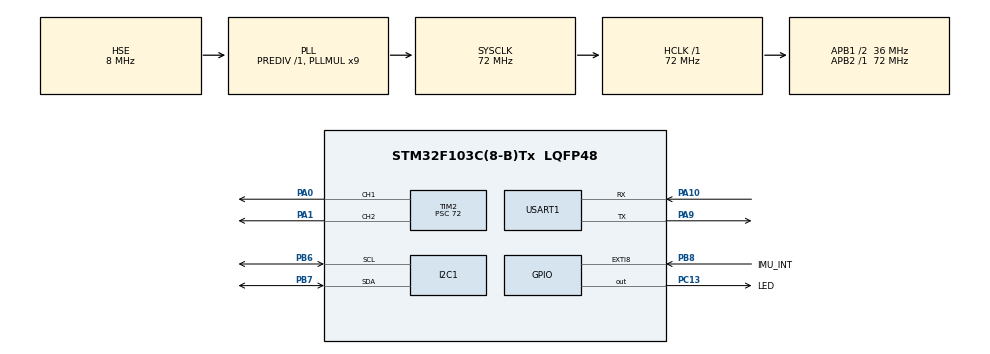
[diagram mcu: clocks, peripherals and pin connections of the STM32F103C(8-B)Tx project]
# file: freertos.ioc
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FREERTOS.MEMORY_ALLOCATION=1
FREERTOS.Tasks01=defaultTask,0,128,StartDefaultTask,Default,NULL,Static,defaultTaskBuffer,defaultTaskControlBlock
Mcu.Family=STM32F1
Mcu.Name=STM32F103C(8-B)Tx
Mcu.Package=LQFP48
NVIC.EXTI9_5_IRQn=true\:5\:0\:false\:false\:true\:true\:true
NVIC.I2C1_ER_IRQn=true\:5\:0\:false\:false\:true\:true\:true
NVIC.I2C1_EV_IRQn=true\:5\:0\:false\:false\:true\:true\:true
NVIC.PriorityGroup=NVIC_PRIORITYGROUP_4
NVIC.TIM1_UP_IRQn=true\:0\:0\:false\:false\:true\:false\:false
NVIC.TimeBase=TIM1_UP_IRQn
NVIC.TimeBaseIP=TIM1
NVIC.USART1_IRQn=true\:5\:0\:false\:false\:true\:true\:true
PA0-WKUP.GPIO_ModeDefaultPP=GPIO_MODE_AF_PP
PA0-WKUP.GPIO_Speed=GPIO_SPEED_FREQ_LOW
PA0-WKUP.Signal=S_TIM2_CH1_ETR
PA1.Signal=S_TIM2_CH2
PA10.Mode=Asynchronous
PA10.Signal=USART1_RX
PA13.Mode=Trace_Asynchronous_SW
PA13.Signal=SYS_JTMS-SWDIO
PA14.Mode=Trace_Asynchronous_SW
PA14.Signal=SYS_JTCK-SWCLK
PA9.Mode=Asynchronous
PA9.Signal=USART1_TX
PB3.Mode=Trace_Asynchronous_SW
PB3.Signal=SYS_JTDO-TRACESWO
PB6.Mode=I2C
PB6.Signal=I2C1_SCL
PB7.Mode=I2C
PB7.Signal=I2C1_SDA
PB8.GPIO_Label=IMU_INT
PB8.GPIO_ModeDefaultEXTI=GPIO_MODE_IT_RISING
PB8.GPIO_PuPd=GPIO_NOPULL
PB8.Signal=GPXTI8
PC13-TAMPER-RTC.GPIO_Label=LED
PC13-TAMPER-RTC.GPIO_ModeDefaultOutputPP=GPIO_MODE_OUTPUT_PP
PC13-TAMPER-RTC.GPIO_PuPd=GPIO_NOPULL
PC13-TAMPER-RTC.GPIO_Speed=GPIO_SPEED_FREQ_LOW
PC13-TAMPER-RTC.PinState=GPIO_PIN_RESET
PC13-TAMPER-RTC.Signal=GPIO_Output
PD0-OSC_IN.Mode=HSE-External-Oscillator
PD0-OSC_IN.Signal=RCC_OSC_IN
PD1-OSC_OUT.Mode=HSE-External-Oscillator
PD1-OSC_OUT.Signal=RCC_OSC_OUT
ProjectManager.HeapSize=0x200
ProjectManager.StackSize=0x400
ProjectManager.TargetToolchain=Makefile
RCC.AHBFreq_Value=72000000
RCC.APB1CLKDivider=RCC_HCLK_DIV2
RCC.APB1Freq_Value=36000000
RCC.APB1TimFreq_Value=72000000
RCC.APB2Freq_Value=72000000
RCC.APB2TimFreq_Value=72000000
RCC.HCLKFreq_Value=72000000
RCC.PLLMUL=RCC_PLL_MUL9
RCC.PLLSourceVirtual=RCC_PLLSOURCE_HSE
RCC.SYSCLKFreq_VALUE=72000000
RCC.SYSCLKSource=RCC_SYSCLKSOURCE_PLLCLK
RCC.USBFreq_Value=72000000
SH.S_TIM2_CH1_ETR.0=TIM2_CH1,PWM Generation1 CH1
SH.S_TIM2_CH2.0=TIM2_CH2,PWM Generation2 CH2
TIM2.Channel-PWM\ Generation1\ CH1=TIM_CHANNEL_1
TIM2.Channel-PWM\ Generation2\ CH2=TIM_CHANNEL_2
TIM2.Period=20000
TIM2.Prescaler=72
USART1.VirtualMode=VM_ASYNC
VP_FREERTOS_VS_ENABLE.Mode=Enabled
VP_SYS_VS_tim1.Mode=TIM1
board=custom

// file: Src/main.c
/**
  ******************************************************************************
  * @file           : main.c
  * @brief          : Main program body
  ******************************************************************************
  * This notice applies to any and all portions of this file
  * that are not between comment pairs USER CODE BEGIN and
  * USER CODE END. Other portions of this file, whether
  * inserted by the user or by software development tools
  * are owned by their respective copyright owners.
  *
  * Copyright (c) 2018 STMicroelectronics International N.V.
  * All rights reserved.
  *
  * Redistribution and use in source and binary forms, with or without
  * modification, are permitted, provided that the following conditions are met:
  *
  * 1. Redistribution of source code must retain the above copyright notice,
  *    this list of conditions and the following disclaimer.
  * 2. Redistributions in binary form must reproduce the above copyright notice,
  *    this list of conditions and the following disclaimer in the documentation
  *    and/or other materials provided with the distribution.
  * 3. Neither the name of STMicroelectronics nor the names of other
  *    contributors to this software may be used to endorse or promote products
  *    derived from this software without specific written permission.
  * 4. This software, including modifications and/or derivative works of this
  *    software, must execute solely and exclusively on microcontroller or
  *    microprocessor devices manufactured by or for STMicroelectronics.
  * 5. Redistribution and use of this software other than as permitted under
  *    this license is void and will automatically terminate your rights under
  *    this license.
  *
  * THIS SOFTWARE IS PROVIDED BY STMICROELECTRONICS AND CONTRIBUTORS "AS IS"
  * AND ANY EXPRESS, IMPLIED OR STATUTORY WARRANTIES, INCLUDING, BUT NOT
  * LIMITED TO, THE IMPLIED WARRANTIES OF MERCHANTABILITY, FITNESS FOR A
  * PARTICULAR PURPOSE AND NON-INFRINGEMENT OF THIRD PARTY INTELLECTUAL PROPERTY
  * RIGHTS ARE DISCLAIMED TO THE FULLEST EXTENT PERMITTED BY LAW. IN NO EVENT
  * SHALL STMICROELECTRONICS OR CONTRIBUTORS BE LIABLE FOR ANY DIRECT, INDIRECT,
  * INCIDENTAL, SPECIAL, EXEMPLARY, OR CONSEQUENTIAL DAMAGES (INCLUDING, BUT NOT
  * LIMITED TO, PROCUREMENT OF SUBSTITUTE GOODS OR SERVICES; LOSS OF USE, DATA,
  * OR PROFITS; OR BUSINESS INTERRUPTION) HOWEVER CAUSED AND ON ANY THEORY OF
  * LIABILITY, WHETHER IN CONTRACT, STRICT LIABILITY, OR TORT (INCLUDING
  * NEGLIGENCE OR OTHERWISE) ARISING IN ANY WAY OUT OF THE USE OF THIS SOFTWARE,
  * EVEN IF ADVISED OF THE POSSIBILITY OF SUCH DAMAGE.
  *
  ******************************************************************************
  */
#include "main.h"
#include "stm32f1xx_hal.h"
#include "cmsis_os.h"

/* USER CODE BEGIN Includes */
#include "FreeRTOS.h"
#include "string.h"
#include "terminal.h"
#include "imu.h"
#include "pwm.h"

/* USER CODE END Includes */

I2C_HandleTypeDef hi2c1;

TIM_HandleTypeDef htim2;

UART_HandleTypeDef huart1;

osThreadId defaultTaskHandle;
uint32_t defaultTaskBuffer[ 128 ];
osStaticThreadDef_t defaultTaskControlBlock;

/* USER CODE BEGIN PV */
/* Private variables ---------------------------------------------------------*/

/* USER CODE END PV */

void SystemClock_Config(void);
static void MX_GPIO_Init(void);
static void MX_USART1_UART_Init(void);
static void MX_I2C1_Init(void);
static void MX_TIM2_Init(void);
void StartDefaultTask(void const * argument);

void HAL_TIM_MspPostInit(TIM_HandleTypeDef *htim);

/* USER CODE BEGIN PFP */
/* Private function prototypes -----------------------------------------------*/

/* USER CODE END PFP */

int main(void)
{

  /* MCU Configuration----------------------------------------------------------*/

  /* Reset of all peripherals, Initializes the Flash interface and the Systick. */
  HAL_Init();

  /* Configure the system clock */
  SystemClock_Config();

  /* Initialize all configured peripherals */
  MX_GPIO_Init();
  MX_USART1_UART_Init();
  MX_I2C1_Init();
  MX_TIM2_Init();
  /* USER CODE BEGIN 2 */

  terminal_init(&huart1);
  imu_init(&hi2c1);
  pwm_init(&htim2);

  /* USER CODE END 2 */

  /* Create the thread(s) */
  /* definition and creation of defaultTask */
  osThreadStaticDef(defaultTask, StartDefaultTask, osPriorityNormal, 0, 128, defaultTaskBuffer, &defaultTaskControlBlock);
  defaultTaskHandle = osThreadCreate(osThread(defaultTask), NULL);

  /* Start scheduler */
  osKernelStart();

  /* We should never get here as control is now taken by the scheduler */

  /* Infinite loop */
  while (1)
  {

  }

}

void SystemClock_Config(void)
{

  RCC_OscInitTypeDef RCC_OscInitStruct;
  RCC_ClkInitTypeDef RCC_ClkInitStruct;

    /**Initializes the CPU, AHB and APB busses clocks
    */
  RCC_OscInitStruct.OscillatorType = RCC_OSCILLATORTYPE_HSE;
  RCC_OscInitStruct.HSEState = RCC_HSE_ON;
  RCC_OscInitStruct.HSEPredivValue = RCC_HSE_PREDIV_DIV1;
  RCC_OscInitStruct.HSIState = RCC_HSI_ON;
  RCC_OscInitStruct.PLL.PLLState = RCC_PLL_ON;
  RCC_OscInitStruct.PLL.PLLSource = RCC_PLLSOURCE_HSE;
  RCC_OscInitStruct.PLL.PLLMUL = RCC_PLL_MUL9;
  if (HAL_RCC_OscConfig(&RCC_OscInitStruct) != HAL_OK)
  {
    _Error_Handler(__FILE__, __LINE__);
  }

    /**Initializes the CPU, AHB and APB busses clocks
    */
  RCC_ClkInitStruct.ClockType = RCC_CLOCKTYPE_HCLK|RCC_CLOCKTYPE_SYSCLK
                              |RCC_CLOCKTYPE_PCLK1|RCC_CLOCKTYPE_PCLK2;
  RCC_ClkInitStruct.SYSCLKSource = RCC_SYSCLKSOURCE_PLLCLK;
  RCC_ClkInitStruct.AHBCLKDivider = RCC_SYSCLK_DIV1;
  RCC_ClkInitStruct.APB1CLKDivider = RCC_HCLK_DIV2;
  RCC_ClkInitStruct.APB2CLKDivider = RCC_HCLK_DIV1;

  if (HAL_RCC_ClockConfig(&RCC_ClkInitStruct, FLASH_LATENCY_2) != HAL_OK)
  {
    _Error_Handler(__FILE__, __LINE__);
  }

    /**Configure the Systick interrupt time
    */
  HAL_SYSTICK_Config(HAL_RCC_GetHCLKFreq()/1000);

    /**Configure the Systick
    */
  HAL_SYSTICK_CLKSourceConfig(SYSTICK_CLKSOURCE_HCLK);

  /* SysTick_IRQn interrupt configuration */
  HAL_NVIC_SetPriority(SysTick_IRQn, 15, 0);
}

/* I2C1 init function */
static void MX_I2C1_Init(void)
{

  hi2c1.Instance = I2C1;
  hi2c1.Init.ClockSpeed = 100000;
  hi2c1.Init.DutyCycle = I2C_DUTYCYCLE_2;
  hi2c1.Init.OwnAddress1 = 0;
  hi2c1.Init.AddressingMode = I2C_ADDRESSINGMODE_7BIT;
  hi2c1.Init.DualAddressMode = I2C_DUALADDRESS_DISABLE;
  hi2c1.Init.OwnAddress2 = 0;
  hi2c1.Init.GeneralCallMode = I2C_GENERALCALL_DISABLE;
  hi2c1.Init.NoStretchMode = I2C_NOSTRETCH_DISABLE;
  if (HAL_I2C_Init(&hi2c1) != HAL_OK)
  {
    _Error_Handler(__FILE__, __LINE__);
  }

}

/* TIM2 init function */
static void MX_TIM2_Init(void)
{

  TIM_MasterConfigTypeDef sMasterConfig;
  TIM_OC_InitTypeDef sConfigOC;

  htim2.Instance = TIM2;
  htim2.Init.Prescaler = 72;
  htim2.Init.CounterMode = TIM_COUNTERMODE_UP;
  htim2.Init.Period = 20000;
  htim2.Init.ClockDivision = TIM_CLOCKDIVISION_DIV1;
  htim2.Init.AutoReloadPreload = TIM_AUTORELOAD_PRELOAD_DISABLE;
  if (HAL_TIM_PWM_Init(&htim2) != HAL_OK)
  {
    _Error_Handler(__FILE__, __LINE__);
  }

  sMasterConfig.MasterOutputTrigger = TIM_TRGO_RESET;
  sMasterConfig.MasterSlaveMode = TIM_MASTERSLAVEMODE_DISABLE;
  if (HAL_TIMEx_MasterConfigSynchronization(&htim2, &sMasterConfig) != HAL_OK)
  {
    _Error_Handler(__FILE__, __LINE__);
  }

  sConfigOC.OCMode = TIM_OCMODE_PWM1;
  sConfigOC.Pulse = 0;
  sConfigOC.OCPolarity = TIM_OCPOLARITY_HIGH;
  sConfigOC.OCFastMode = TIM_OCFAST_DISABLE;
  if (HAL_TIM_PWM_ConfigChannel(&htim2, &sConfigOC, TIM_CHANNEL_1) != HAL_OK)
  {
    _Error_Handler(__FILE__, __LINE__);
  }

  if (HAL_TIM_PWM_ConfigChannel(&htim2, &sConfigOC, TIM_CHANNEL_2) != HAL_OK)
  {
    _Error_Handler(__FILE__, __LINE__);
  }

  HAL_TIM_MspPostInit(&htim2);

}

/* USART1 init function */
static void MX_USART1_UART_Init(void)
{

  huart1.Instance = USART1;
  huart1.Init.BaudRate = 115200;
  huart1.Init.WordLength = UART_WORDLENGTH_8B;
  huart1.Init.StopBits = UART_STOPBITS_1;
  huart1.Init.Parity = UART_PARITY_NONE;
  huart1.Init.Mode = UART_MODE_TX_RX;
  huart1.Init.HwFlowCtl = UART_HWCONTROL_NONE;
  huart1.Init.OverSampling = UART_OVERSAMPLING_16;
  if (HAL_UART_Init(&huart1) != HAL_OK)
  {
    _Error_Handler(__FILE__, __LINE__);
  }

}

/** Configure pins as
        * Analog
        * Input
        * Output
        * EVENT_OUT
        * EXTI
*/
static void MX_GPIO_Init(void)
{

  GPIO_InitTypeDef GPIO_InitStruct;

  /* GPIO Ports Clock Enable */
  __HAL_RCC_GPIOC_CLK_ENABLE();
  __HAL_RCC_GPIOD_CLK_ENABLE();
  __HAL_RCC_GPIOA_CLK_ENABLE();
  __HAL_RCC_GPIOB_CLK_ENABLE();

  /*Configure GPIO pin Output Level */
  HAL_GPIO_WritePin(LED_GPIO_Port, LED_Pin, GPIO_PIN_RESET);

  /*Configure GPIO pin : LED_Pin */
  GPIO_InitStruct.Pin = LED_Pin;
  GPIO_InitStruct.Mode = GPIO_MODE_OUTPUT_PP;
  GPIO_InitStruct.Pull = GPIO_NOPULL;
  GPIO_InitStruct.Speed = GPIO_SPEED_FREQ_LOW;
  HAL_GPIO_Init(LED_GPIO_Port, &GPIO_InitStruct);

  /*Configure GPIO pin : IMU_INT_Pin */
  GPIO_InitStruct.Pin = IMU_INT_Pin;
  GPIO_InitStruct.Mode = GPIO_MODE_IT_RISING;
  GPIO_InitStruct.Pull = GPIO_NOPULL;
  HAL_GPIO_Init(IMU_INT_GPIO_Port, &GPIO_InitStruct);

  /* EXTI interrupt init*/
  HAL_NVIC_SetPriority(EXTI9_5_IRQn, 5, 0);
  HAL_NVIC_EnableIRQ(EXTI9_5_IRQn);

}

/* USER CODE BEGIN 4 */
void HAL_UART_RxCpltCallback(UART_HandleTypeDef *huart) {
  if (huart == terminal_huart) {
    TerminalRxCallback();
  }
}

/* USER CODE END 4 */

void StartDefaultTask(void const * argument)
{

  /* USER CODE BEGIN 5 */
  //char *string = "Hello world!\n";
  //char read[100];
  /* Infinite loop */
  for(;;)
  {
    // Blink the LED
    LED_GPIO_Port->ODR ^= LED_Pin;
    osDelay(1000);
    /*
    HAL_UART_Transmit(&huart1, (uint8_t *)string, strlen(string), 1000);
    HAL_UART_Receive(&huart1, (uint8_t *)read, 100, 1000);
    if (memcmp(read, "on", strlen("on")) == 0) {
      led_config = 1;
    } else if (memcmp(read, "off", strlen("off")) == 0) {
      led_config = 0;
    }
    */
  }
  /* USER CODE END 5 */
}

void HAL_TIM_PeriodElapsedCallback(TIM_HandleTypeDef *htim)
{
  if (htim->Instance == TIM1) {
    HAL_IncTick();
  }
}

void _Error_Handler(char *file, int line)
{
  while(1)
  {
  }
}

/************************ (C) COPYRIGHT STMicroelectronics *****END OF FILE****/

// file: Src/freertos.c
/* USER CODE BEGIN Header */
/**
  ******************************************************************************
  * File Name          : freertos.c
  * Description        : Code for freertos applications
  ******************************************************************************
  * This notice applies to any and all portions of this file
  * that are not between comment pairs USER CODE BEGIN and
  * USER CODE END. Other portions of this file, whether
  * inserted by the user or by software development tools
  * are owned by their respective copyright owners.
  *
  * Copyright (c) 2018 STMicroelectronics International N.V.
  * All rights reserved.
  *
  * Redistribution and use in source and binary forms, with or without
  * modification, are permitted, provided that the following conditions are met:
  *
  * 1. Redistribution of source code must retain the above copyright notice,
  *    this list of conditions and the following disclaimer.
  * 2. Redistributions in binary form must reproduce the above copyright notice,
  *    this list of conditions and the following disclaimer in the documentation
  *    and/or other materials provided with the distribution.
  * 3. Neither the name of STMicroelectronics nor the names of other
  *    contributors to this software may be used to endorse or promote products
  *    derived from this software without specific written permission.
  * 4. This software, including modifications and/or derivative works of this
  *    software, must execute solely and exclusively on microcontroller or
  *    microprocessor devices manufactured by or for STMicroelectronics.
  * 5. Redistribution and use of this software other than as permitted under
  *    this license is void and will automatically terminate your rights under
  *    this license.
  *
  * THIS SOFTWARE IS PROVIDED BY STMICROELECTRONICS AND CONTRIBUTORS "AS IS"
  * AND ANY EXPRESS, IMPLIED OR STATUTORY WARRANTIES, INCLUDING, BUT NOT
  * LIMITED TO, THE IMPLIED WARRANTIES OF MERCHANTABILITY, FITNESS FOR A
  * PARTICULAR PURPOSE AND NON-INFRINGEMENT OF THIRD PARTY INTELLECTUAL PROPERTY
  * RIGHTS ARE DISCLAIMED TO THE FULLEST EXTENT PERMITTED BY LAW. IN NO EVENT
  * SHALL STMICROELECTRONICS OR CONTRIBUTORS BE LIABLE FOR ANY DIRECT, INDIRECT,
  * INCIDENTAL, SPECIAL, EXEMPLARY, OR CONSEQUENTIAL DAMAGES (INCLUDING, BUT NOT
  * LIMITED TO, PROCUREMENT OF SUBSTITUTE GOODS OR SERVICES; LOSS OF USE, DATA,
  * OR PROFITS; OR BUSINESS INTERRUPTION) HOWEVER CAUSED AND ON ANY THEORY OF
  * LIABILITY, WHETHER IN CONTRACT, STRICT LIABILITY, OR TORT (INCLUDING
  * NEGLIGENCE OR OTHERWISE) ARISING IN ANY WAY OUT OF THE USE OF THIS SOFTWARE,
  * EVEN IF ADVISED OF THE POSSIBILITY OF SUCH DAMAGE.
  *
  ******************************************************************************
  */
/* USER CODE END Header */

#include "FreeRTOS.h"
#include "task.h"
#include "main.h"

/* GetIdleTaskMemory prototype (linked to static allocation support) */
void vApplicationGetIdleTaskMemory( StaticTask_t **ppxIdleTaskTCBBuffer, StackType_t **ppxIdleTaskStackBuffer, uint32_t *pulIdleTaskStackSize );

/* USER CODE BEGIN GET_IDLE_TASK_MEMORY */
static StaticTask_t xIdleTaskTCBBuffer;
static StackType_t xIdleStack[configMINIMAL_STACK_SIZE];

void vApplicationGetIdleTaskMemory( StaticTask_t **ppxIdleTaskTCBBuffer, StackType_t **ppxIdleTaskStackBuffer, uint32_t *pulIdleTaskStackSize )
{
  *ppxIdleTaskTCBBuffer = &xIdleTaskTCBBuffer;
  *ppxIdleTaskStackBuffer = &xIdleStack[0];
  *pulIdleTaskStackSize = configMINIMAL_STACK_SIZE;
  /* place for user code */
}
/* USER CODE END GET_IDLE_TASK_MEMORY */

/************************ (C) COPYRIGHT STMicroelectronics *****END OF FILE****/
